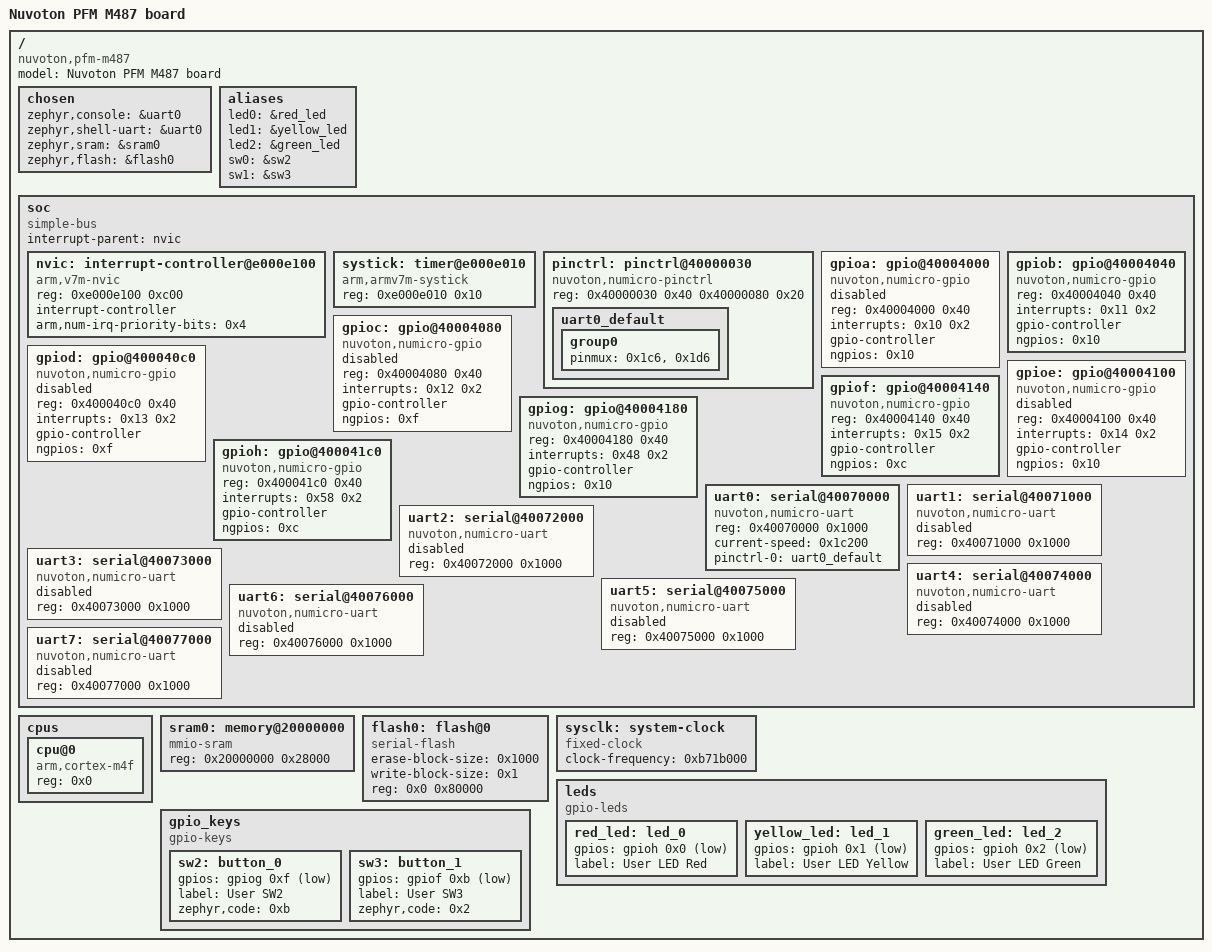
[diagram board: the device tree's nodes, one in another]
/dts-v1/;

/* node '/' defined in zephyr/dts/common/skeleton.dtsi:9 */
/ {
	#address-cells = < 0x1 >;         /* in zephyr/dts/common/skeleton.dtsi:10 */
	#size-cells = < 0x1 >;            /* in zephyr/dts/common/skeleton.dtsi:11 */
	model = "Nuvoton PFM M487 board"; /* in zephyr/boards/nuvoton/numaker_pfm_m487/numaker_pfm_m487.dts:13 */
	compatible = "nuvoton,pfm-m487",
	             "nuvoton,m487";      /* in zephyr/boards/nuvoton/numaker_pfm_m487/numaker_pfm_m487.dts:14 */

	/* node '/chosen' defined in zephyr/dts/common/skeleton.dtsi:13 */
	chosen {
		zephyr,console = &uart0;    /* in zephyr/boards/nuvoton/numaker_pfm_m487/numaker_pfm_m487.dts:25 */
		zephyr,shell-uart = &uart0; /* in zephyr/boards/nuvoton/numaker_pfm_m487/numaker_pfm_m487.dts:26 */
		zephyr,sram = &sram0;       /* in zephyr/boards/nuvoton/numaker_pfm_m487/numaker_pfm_m487.dts:27 */
		zephyr,flash = &flash0;     /* in zephyr/boards/nuvoton/numaker_pfm_m487/numaker_pfm_m487.dts:28 */
	};

	/* node '/aliases' defined in zephyr/dts/common/skeleton.dtsi:15 */
	aliases {
		led0 = &red_led;    /* in zephyr/boards/nuvoton/numaker_pfm_m487/numaker_pfm_m487.dts:17 */
		led1 = &yellow_led; /* in zephyr/boards/nuvoton/numaker_pfm_m487/numaker_pfm_m487.dts:18 */
		led2 = &green_led;  /* in zephyr/boards/nuvoton/numaker_pfm_m487/numaker_pfm_m487.dts:19 */
		sw0 = &sw2;         /* in zephyr/boards/nuvoton/numaker_pfm_m487/numaker_pfm_m487.dts:20 */
		sw1 = &sw3;         /* in zephyr/boards/nuvoton/numaker_pfm_m487/numaker_pfm_m487.dts:21 */
	};

	/* node '/soc' defined in zephyr/dts/arm/armv7-m.dtsi:6 */
	soc {
		#address-cells = < 0x1 >;     /* in zephyr/dts/arm/armv7-m.dtsi:7 */
		#size-cells = < 0x1 >;        /* in zephyr/dts/arm/armv7-m.dtsi:8 */
		compatible = "simple-bus";    /* in zephyr/dts/arm/armv7-m.dtsi:9 */
		interrupt-parent = < &nvic >; /* in zephyr/dts/arm/armv7-m.dtsi:10 */
		ranges;                       /* in zephyr/dts/arm/armv7-m.dtsi:11 */

		/* node '/soc/interrupt-controller@e000e100' defined in zephyr/dts/arm/armv7-m.dtsi:13 */
		nvic: interrupt-controller@e000e100 {
			#address-cells = < 0x1 >;            /* in zephyr/dts/arm/armv7-m.dtsi:14 */
			compatible = "arm,v7m-nvic";         /* in zephyr/dts/arm/armv7-m.dtsi:15 */
			reg = < 0xe000e100 0xc00 >;          /* in zephyr/dts/arm/armv7-m.dtsi:16 */
			interrupt-controller;                /* in zephyr/dts/arm/armv7-m.dtsi:17 */
			#interrupt-cells = < 0x2 >;          /* in zephyr/dts/arm/armv7-m.dtsi:18 */
			arm,num-irq-priority-bits = < 0x4 >; /* in zephyr/dts/arm/nuvoton/m48x.dtsi:179 */
			phandle = < 0x1 >;                   /* in zephyr/dts/arm/armv7-m.dtsi:10 */
		};

		/* node '/soc/timer@e000e010' defined in zephyr/dts/arm/armv7-m.dtsi:21 */
		systick: timer@e000e010 {
			compatible = "arm,armv7m-systick"; /* in zephyr/dts/arm/armv7-m.dtsi:22 */
			reg = < 0xe000e010 0x10 >;         /* in zephyr/dts/arm/armv7-m.dtsi:23 */
		};

		/* node '/soc/pinctrl@40000030' defined in zephyr/dts/arm/nuvoton/m48x.dtsi:40 */
		pinctrl: pinctrl@40000030 {
			compatible = "nuvoton,numicro-pinctrl";    /* in zephyr/dts/arm/nuvoton/m48x.dtsi:41 */
			reg = < 0x40000030 0x40 0x40000080 0x20 >; /* in zephyr/dts/arm/nuvoton/m48x.dtsi:42 */
			reg-names = "mfp",
			            "mfos";                        /* in zephyr/dts/arm/nuvoton/m48x.dtsi:44 */
			status = "okay";                           /* in zephyr/dts/arm/nuvoton/m48x.dtsi:45 */

			/* node '/soc/pinctrl@40000030/uart0_default' defined in zephyr/boards/nuvoton/numaker_pfm_m487/numaker_pfm_m487-pinctrl.dtsi:10 */
			uart0_default: uart0_default {
				phandle = < 0x2 >; /* in zephyr/boards/nuvoton/numaker_pfm_m487/numaker_pfm_m487.dts:94 */

				/* node '/soc/pinctrl@40000030/uart0_default/group0' defined in zephyr/boards/nuvoton/numaker_pfm_m487/numaker_pfm_m487-pinctrl.dtsi:11 */
				group0 {
					pinmux = < 0x1c6 >,
					         < 0x1d6 >; /* in zephyr/boards/nuvoton/numaker_pfm_m487/numaker_pfm_m487-pinctrl.dtsi:12 */
				};
			};
		};

		/* node '/soc/gpio@40004000' defined in zephyr/dts/arm/nuvoton/m48x.dtsi:48 */
		gpioa: gpio@40004000 {
			compatible = "nuvoton,numicro-gpio"; /* in zephyr/dts/arm/nuvoton/m48x.dtsi:49 */
			reg = < 0x40004000 0x40 >;           /* in zephyr/dts/arm/nuvoton/m48x.dtsi:50 */
			status = "disabled";                 /* in zephyr/dts/arm/nuvoton/m48x.dtsi:51 */
			interrupts = < 0x10 0x2 >;           /* in zephyr/dts/arm/nuvoton/m48x.dtsi:52 */
			gpio-controller;                     /* in zephyr/dts/arm/nuvoton/m48x.dtsi:53 */
			#gpio-cells = < 0x2 >;               /* in zephyr/dts/arm/nuvoton/m48x.dtsi:54 */
			ngpios = < 0x10 >;                   /* in zephyr/dts/arm/nuvoton/m48x.dtsi:55 */
		};

		/* node '/soc/gpio@40004040' defined in zephyr/dts/arm/nuvoton/m48x.dtsi:58 */
		gpiob: gpio@40004040 {
			compatible = "nuvoton,numicro-gpio"; /* in zephyr/dts/arm/nuvoton/m48x.dtsi:59 */
			reg = < 0x40004040 0x40 >;           /* in zephyr/dts/arm/nuvoton/m48x.dtsi:60 */
			interrupts = < 0x11 0x2 >;           /* in zephyr/dts/arm/nuvoton/m48x.dtsi:62 */
			gpio-controller;                     /* in zephyr/dts/arm/nuvoton/m48x.dtsi:63 */
			#gpio-cells = < 0x2 >;               /* in zephyr/dts/arm/nuvoton/m48x.dtsi:64 */
			ngpios = < 0x10 >;                   /* in zephyr/dts/arm/nuvoton/m48x.dtsi:65 */
			status = "okay";                     /* in zephyr/boards/nuvoton/numaker_pfm_m487/numaker_pfm_m487.dts:76 */
		};

		/* node '/soc/gpio@40004080' defined in zephyr/dts/arm/nuvoton/m48x.dtsi:68 */
		gpioc: gpio@40004080 {
			compatible = "nuvoton,numicro-gpio"; /* in zephyr/dts/arm/nuvoton/m48x.dtsi:69 */
			reg = < 0x40004080 0x40 >;           /* in zephyr/dts/arm/nuvoton/m48x.dtsi:70 */
			status = "disabled";                 /* in zephyr/dts/arm/nuvoton/m48x.dtsi:71 */
			interrupts = < 0x12 0x2 >;           /* in zephyr/dts/arm/nuvoton/m48x.dtsi:72 */
			gpio-controller;                     /* in zephyr/dts/arm/nuvoton/m48x.dtsi:73 */
			#gpio-cells = < 0x2 >;               /* in zephyr/dts/arm/nuvoton/m48x.dtsi:74 */
			ngpios = < 0xf >;                    /* in zephyr/dts/arm/nuvoton/m48x.dtsi:75 */
		};

		/* node '/soc/gpio@400040c0' defined in zephyr/dts/arm/nuvoton/m48x.dtsi:78 */
		gpiod: gpio@400040c0 {
			compatible = "nuvoton,numicro-gpio"; /* in zephyr/dts/arm/nuvoton/m48x.dtsi:79 */
			reg = < 0x400040c0 0x40 >;           /* in zephyr/dts/arm/nuvoton/m48x.dtsi:80 */
			status = "disabled";                 /* in zephyr/dts/arm/nuvoton/m48x.dtsi:81 */
			interrupts = < 0x13 0x2 >;           /* in zephyr/dts/arm/nuvoton/m48x.dtsi:82 */
			gpio-controller;                     /* in zephyr/dts/arm/nuvoton/m48x.dtsi:83 */
			#gpio-cells = < 0x2 >;               /* in zephyr/dts/arm/nuvoton/m48x.dtsi:84 */
			ngpios = < 0xf >;                    /* in zephyr/dts/arm/nuvoton/m48x.dtsi:85 */
		};

		/* node '/soc/gpio@40004100' defined in zephyr/dts/arm/nuvoton/m48x.dtsi:88 */
		gpioe: gpio@40004100 {
			compatible = "nuvoton,numicro-gpio"; /* in zephyr/dts/arm/nuvoton/m48x.dtsi:89 */
			reg = < 0x40004100 0x40 >;           /* in zephyr/dts/arm/nuvoton/m48x.dtsi:90 */
			status = "disabled";                 /* in zephyr/dts/arm/nuvoton/m48x.dtsi:91 */
			interrupts = < 0x14 0x2 >;           /* in zephyr/dts/arm/nuvoton/m48x.dtsi:92 */
			gpio-controller;                     /* in zephyr/dts/arm/nuvoton/m48x.dtsi:93 */
			#gpio-cells = < 0x2 >;               /* in zephyr/dts/arm/nuvoton/m48x.dtsi:94 */
			ngpios = < 0x10 >;                   /* in zephyr/dts/arm/nuvoton/m48x.dtsi:95 */
		};

		/* node '/soc/gpio@40004140' defined in zephyr/dts/arm/nuvoton/m48x.dtsi:98 */
		gpiof: gpio@40004140 {
			compatible = "nuvoton,numicro-gpio"; /* in zephyr/dts/arm/nuvoton/m48x.dtsi:99 */
			reg = < 0x40004140 0x40 >;           /* in zephyr/dts/arm/nuvoton/m48x.dtsi:100 */
			interrupts = < 0x15 0x2 >;           /* in zephyr/dts/arm/nuvoton/m48x.dtsi:102 */
			gpio-controller;                     /* in zephyr/dts/arm/nuvoton/m48x.dtsi:103 */
			#gpio-cells = < 0x2 >;               /* in zephyr/dts/arm/nuvoton/m48x.dtsi:104 */
			ngpios = < 0xc >;                    /* in zephyr/dts/arm/nuvoton/m48x.dtsi:105 */
			status = "okay";                     /* in zephyr/boards/nuvoton/numaker_pfm_m487/numaker_pfm_m487.dts:80 */
			phandle = < 0x5 >;                   /* in zephyr/boards/nuvoton/numaker_pfm_m487/numaker_pfm_m487.dts:60 */
		};

		/* node '/soc/gpio@40004180' defined in zephyr/dts/arm/nuvoton/m48x.dtsi:108 */
		gpiog: gpio@40004180 {
			compatible = "nuvoton,numicro-gpio"; /* in zephyr/dts/arm/nuvoton/m48x.dtsi:109 */
			reg = < 0x40004180 0x40 >;           /* in zephyr/dts/arm/nuvoton/m48x.dtsi:110 */
			interrupts = < 0x48 0x2 >;           /* in zephyr/dts/arm/nuvoton/m48x.dtsi:112 */
			gpio-controller;                     /* in zephyr/dts/arm/nuvoton/m48x.dtsi:113 */
			#gpio-cells = < 0x2 >;               /* in zephyr/dts/arm/nuvoton/m48x.dtsi:114 */
			ngpios = < 0x10 >;                   /* in zephyr/dts/arm/nuvoton/m48x.dtsi:115 */
			status = "okay";                     /* in zephyr/boards/nuvoton/numaker_pfm_m487/numaker_pfm_m487.dts:84 */
			phandle = < 0x4 >;                   /* in zephyr/boards/nuvoton/numaker_pfm_m487/numaker_pfm_m487.dts:54 */
		};

		/* node '/soc/gpio@400041c0' defined in zephyr/dts/arm/nuvoton/m48x.dtsi:118 */
		gpioh: gpio@400041c0 {
			compatible = "nuvoton,numicro-gpio"; /* in zephyr/dts/arm/nuvoton/m48x.dtsi:119 */
			reg = < 0x400041c0 0x40 >;           /* in zephyr/dts/arm/nuvoton/m48x.dtsi:120 */
			interrupts = < 0x58 0x2 >;           /* in zephyr/dts/arm/nuvoton/m48x.dtsi:122 */
			gpio-controller;                     /* in zephyr/dts/arm/nuvoton/m48x.dtsi:123 */
			#gpio-cells = < 0x2 >;               /* in zephyr/dts/arm/nuvoton/m48x.dtsi:124 */
			ngpios = < 0xc >;                    /* in zephyr/dts/arm/nuvoton/m48x.dtsi:125 */
			status = "okay";                     /* in zephyr/boards/nuvoton/numaker_pfm_m487/numaker_pfm_m487.dts:88 */
			phandle = < 0x3 >;                   /* in zephyr/boards/nuvoton/numaker_pfm_m487/numaker_pfm_m487.dts:35 */
		};

		/* node '/soc/serial@40070000' defined in zephyr/dts/arm/nuvoton/m48x.dtsi:128 */
		uart0: serial@40070000 {
			compatible = "nuvoton,numicro-uart"; /* in zephyr/dts/arm/nuvoton/m48x.dtsi:129 */
			reg = < 0x40070000 0x1000 >;         /* in zephyr/dts/arm/nuvoton/m48x.dtsi:130 */
			current-speed = < 0x1c200 >;         /* in zephyr/boards/nuvoton/numaker_pfm_m487/numaker_pfm_m487.dts:92 */
			status = "okay";                     /* in zephyr/boards/nuvoton/numaker_pfm_m487/numaker_pfm_m487.dts:93 */
			pinctrl-0 = < &uart0_default >;      /* in zephyr/boards/nuvoton/numaker_pfm_m487/numaker_pfm_m487.dts:94 */
			pinctrl-names = "default";           /* in zephyr/boards/nuvoton/numaker_pfm_m487/numaker_pfm_m487.dts:95 */
		};

		/* node '/soc/serial@40071000' defined in zephyr/dts/arm/nuvoton/m48x.dtsi:134 */
		uart1: serial@40071000 {
			compatible = "nuvoton,numicro-uart"; /* in zephyr/dts/arm/nuvoton/m48x.dtsi:135 */
			reg = < 0x40071000 0x1000 >;         /* in zephyr/dts/arm/nuvoton/m48x.dtsi:136 */
			status = "disabled";                 /* in zephyr/dts/arm/nuvoton/m48x.dtsi:137 */
		};

		/* node '/soc/serial@40072000' defined in zephyr/dts/arm/nuvoton/m48x.dtsi:140 */
		uart2: serial@40072000 {
			compatible = "nuvoton,numicro-uart"; /* in zephyr/dts/arm/nuvoton/m48x.dtsi:141 */
			reg = < 0x40072000 0x1000 >;         /* in zephyr/dts/arm/nuvoton/m48x.dtsi:142 */
			status = "disabled";                 /* in zephyr/dts/arm/nuvoton/m48x.dtsi:143 */
		};

		/* node '/soc/serial@40073000' defined in zephyr/dts/arm/nuvoton/m48x.dtsi:146 */
		uart3: serial@40073000 {
			compatible = "nuvoton,numicro-uart"; /* in zephyr/dts/arm/nuvoton/m48x.dtsi:147 */
			reg = < 0x40073000 0x1000 >;         /* in zephyr/dts/arm/nuvoton/m48x.dtsi:148 */
			status = "disabled";                 /* in zephyr/dts/arm/nuvoton/m48x.dtsi:149 */
		};

		/* node '/soc/serial@40074000' defined in zephyr/dts/arm/nuvoton/m48x.dtsi:152 */
		uart4: serial@40074000 {
			compatible = "nuvoton,numicro-uart"; /* in zephyr/dts/arm/nuvoton/m48x.dtsi:153 */
			reg = < 0x40074000 0x1000 >;         /* in zephyr/dts/arm/nuvoton/m48x.dtsi:154 */
			status = "disabled";                 /* in zephyr/dts/arm/nuvoton/m48x.dtsi:155 */
		};

		/* node '/soc/serial@40075000' defined in zephyr/dts/arm/nuvoton/m48x.dtsi:158 */
		uart5: serial@40075000 {
			compatible = "nuvoton,numicro-uart"; /* in zephyr/dts/arm/nuvoton/m48x.dtsi:159 */
			reg = < 0x40075000 0x1000 >;         /* in zephyr/dts/arm/nuvoton/m48x.dtsi:160 */
			status = "disabled";                 /* in zephyr/dts/arm/nuvoton/m48x.dtsi:161 */
		};

		/* node '/soc/serial@40076000' defined in zephyr/dts/arm/nuvoton/m48x.dtsi:164 */
		uart6: serial@40076000 {
			compatible = "nuvoton,numicro-uart"; /* in zephyr/dts/arm/nuvoton/m48x.dtsi:165 */
			reg = < 0x40076000 0x1000 >;         /* in zephyr/dts/arm/nuvoton/m48x.dtsi:166 */
			status = "disabled";                 /* in zephyr/dts/arm/nuvoton/m48x.dtsi:167 */
		};

		/* node '/soc/serial@40077000' defined in zephyr/dts/arm/nuvoton/m48x.dtsi:170 */
		uart7: serial@40077000 {
			compatible = "nuvoton,numicro-uart"; /* in zephyr/dts/arm/nuvoton/m48x.dtsi:171 */
			reg = < 0x40077000 0x1000 >;         /* in zephyr/dts/arm/nuvoton/m48x.dtsi:172 */
			status = "disabled";                 /* in zephyr/dts/arm/nuvoton/m48x.dtsi:173 */
		};
	};

	/* node '/cpus' defined in zephyr/dts/arm/nuvoton/m48x.dtsi:12 */
	cpus {
		#address-cells = < 0x1 >; /* in zephyr/dts/arm/nuvoton/m48x.dtsi:13 */
		#size-cells = < 0x0 >;    /* in zephyr/dts/arm/nuvoton/m48x.dtsi:14 */

		/* node '/cpus/cpu@0' defined in zephyr/dts/arm/nuvoton/m48x.dtsi:16 */
		cpu@0 {
			device_type = "cpu";           /* in zephyr/dts/arm/nuvoton/m48x.dtsi:17 */
			compatible = "arm,cortex-m4f"; /* in zephyr/dts/arm/nuvoton/m48x.dtsi:18 */
			reg = < 0x0 >;                 /* in zephyr/dts/arm/nuvoton/m48x.dtsi:19 */
		};
	};

	/* node '/memory@20000000' defined in zephyr/dts/arm/nuvoton/m48x.dtsi:23 */
	sram0: memory@20000000 {
		compatible = "mmio-sram";     /* in zephyr/dts/arm/nuvoton/m48x.dtsi:24 */
		reg = < 0x20000000 0x28000 >; /* in zephyr/boards/nuvoton/numaker_pfm_m487/numaker_pfm_m487.dts:72 */
	};

	/* node '/flash@0' defined in zephyr/dts/arm/nuvoton/m48x.dtsi:27 */
	flash0: flash@0 {
		compatible = "serial-flash";   /* in zephyr/dts/arm/nuvoton/m48x.dtsi:28 */
		erase-block-size = < 0x1000 >; /* in zephyr/dts/arm/nuvoton/m48x.dtsi:29 */
		write-block-size = < 0x1 >;    /* in zephyr/dts/arm/nuvoton/m48x.dtsi:30 */
		reg = < 0x0 0x80000 >;         /* in zephyr/boards/nuvoton/numaker_pfm_m487/numaker_pfm_m487.dts:68 */
	};

	/* node '/system-clock' defined in zephyr/dts/arm/nuvoton/m48x.dtsi:33 */
	sysclk: system-clock {
		compatible = "fixed-clock";      /* in zephyr/dts/arm/nuvoton/m48x.dtsi:34 */
		clock-frequency = < 0xb71b000 >; /* in zephyr/dts/arm/nuvoton/m48x.dtsi:35 */
		#clock-cells = < 0x0 >;          /* in zephyr/dts/arm/nuvoton/m48x.dtsi:36 */
	};

	/* node '/leds' defined in zephyr/boards/nuvoton/numaker_pfm_m487/numaker_pfm_m487.dts:31 */
	leds {
		compatible = "gpio-leds"; /* in zephyr/boards/nuvoton/numaker_pfm_m487/numaker_pfm_m487.dts:32 */

		/* node '/leds/led_0' defined in zephyr/boards/nuvoton/numaker_pfm_m487/numaker_pfm_m487.dts:34 */
		red_led: led_0 {
			gpios = < &gpioh 0x0 0x1 >; /* in zephyr/boards/nuvoton/numaker_pfm_m487/numaker_pfm_m487.dts:35 */
			label = "User LED Red";     /* in zephyr/boards/nuvoton/numaker_pfm_m487/numaker_pfm_m487.dts:36 */
		};

		/* node '/leds/led_1' defined in zephyr/boards/nuvoton/numaker_pfm_m487/numaker_pfm_m487.dts:39 */
		yellow_led: led_1 {
			gpios = < &gpioh 0x1 0x1 >; /* in zephyr/boards/nuvoton/numaker_pfm_m487/numaker_pfm_m487.dts:40 */
			label = "User LED Yellow";  /* in zephyr/boards/nuvoton/numaker_pfm_m487/numaker_pfm_m487.dts:41 */
		};

		/* node '/leds/led_2' defined in zephyr/boards/nuvoton/numaker_pfm_m487/numaker_pfm_m487.dts:44 */
		green_led: led_2 {
			gpios = < &gpioh 0x2 0x1 >; /* in zephyr/boards/nuvoton/numaker_pfm_m487/numaker_pfm_m487.dts:45 */
			label = "User LED Green";   /* in zephyr/boards/nuvoton/numaker_pfm_m487/numaker_pfm_m487.dts:46 */
		};
	};

	/* node '/gpio_keys' defined in zephyr/boards/nuvoton/numaker_pfm_m487/numaker_pfm_m487.dts:50 */
	gpio_keys {
		compatible = "gpio-keys"; /* in zephyr/boards/nuvoton/numaker_pfm_m487/numaker_pfm_m487.dts:51 */

		/* node '/gpio_keys/button_0' defined in zephyr/boards/nuvoton/numaker_pfm_m487/numaker_pfm_m487.dts:53 */
		sw2: button_0 {
			gpios = < &gpiog 0xf 0x1 >; /* in zephyr/boards/nuvoton/numaker_pfm_m487/numaker_pfm_m487.dts:54 */
			label = "User SW2";         /* in zephyr/boards/nuvoton/numaker_pfm_m487/numaker_pfm_m487.dts:55 */
			zephyr,code = < 0xb >;      /* in zephyr/boards/nuvoton/numaker_pfm_m487/numaker_pfm_m487.dts:56 */
		};

		/* node '/gpio_keys/button_1' defined in zephyr/boards/nuvoton/numaker_pfm_m487/numaker_pfm_m487.dts:59 */
		sw3: button_1 {
			gpios = < &gpiof 0xb 0x1 >; /* in zephyr/boards/nuvoton/numaker_pfm_m487/numaker_pfm_m487.dts:60 */
			label = "User SW3";         /* in zephyr/boards/nuvoton/numaker_pfm_m487/numaker_pfm_m487.dts:61 */
			zephyr,code = < 0x2 >;      /* in zephyr/boards/nuvoton/numaker_pfm_m487/numaker_pfm_m487.dts:62 */
		};
	};
};
